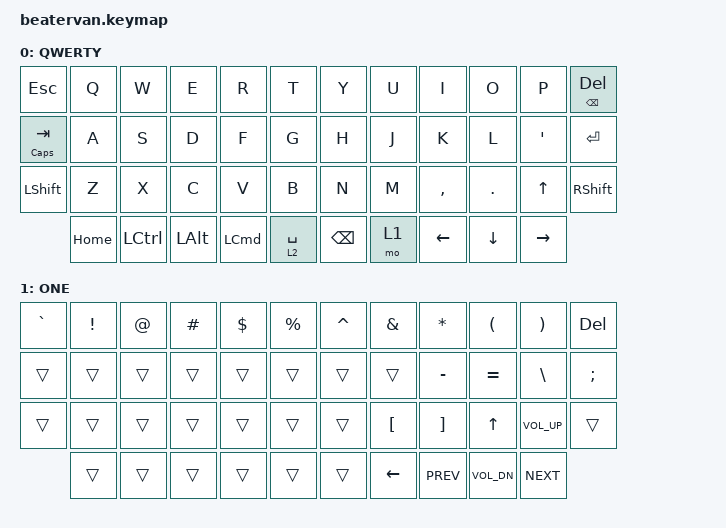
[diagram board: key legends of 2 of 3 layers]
/*
 * Copyright (c) 2020 The ZMK Contributors
 *
 * SPDX-License-Identifier: MIT
 */

#include <behaviors.dtsi>
#include <dt-bindings/zmk/keys.h>
#include <dt-bindings/zmk/bt.h>

#define QWERTY 0
#define ONE 1
#define TWO 2

/ {
	behaviors {
		ht: hold_tap {
			compatible = "zmk,behavior-hold-tap";
			label = "Hold Tap";
			#binding-cells = <2>;
			tapping-term-ms = <200>;
			flavor = "tap-preferred";
			bindings = <&kp>, <&kp>;
		};
	};

	keymap {
		compatible = "zmk,keymap";

		default_layer {
			label = "QWERTY";
			bindings = <
&kp ESC      &kp Q    &kp W    &kp E       &kp R &kp T &kp Y &kp U    &kp I     &kp O    &kp P    &ht BSPC DEL
&ht CAPS TAB   &kp A    &kp S    &kp D       &kp F &kp G &kp H &kp J    &kp K     &kp L    &kp APOS &kp RET
&kp LSHFT         &kp Z    &kp X    &kp C       &kp V &kp B &kp N &kp M    &kp COMMA &kp DOT  &kp UP   &kp RSHFT
&kp HOME     &kp LCTRL &kp LALT &kp LCMD         &lt 2 SPACE   &kp BSPC &mo 1     &kp LEFT &kp DOWN &kp RIGHT
			>;
		};

		first_layer {
			label = "ONE";
			bindings = <
&kp GRAVE &kp EXCL &kp AT &kp HASH &kp DOLLAR &kp PERCENT &kp CARET &kp AMPS &kp STAR &kp LPAR &kp RPAR &kp DEL
&trans     &trans &trans &trans &trans &trans &trans &trans &kp MINUS &kp EQUAL &kp BSLH  &kp SEMI
&trans    &trans  &trans &trans &trans &trans &trans   &kp LBKT   &kp RBKT    &kp UP    &kp C_VOL_UP   &trans
&trans    &trans   &trans    &trans                        &trans   &trans    &kp LEFT  &kp C_PREV    &kp C_VOL_DN &kp C_NEXT
			>;
		};

		second_layer {
			label = "TWO";
			bindings = <
&trans &kp N7 &kp N8 &kp N9 &bt BT_CLR &bt BT_PRV &bt BT_NXT &trans &trans  &trans  &trans  &trans
&trans &kp N4 &kp N5 &kp N6 &trans     &trans     &trans     &trans &trans  &trans  &trans  &trans
&trans &kp N1 &kp N2 &kp N3 &kp N0     &trans     &trans     &trans &trans  &trans  &trans  &trans
&trans    &trans     &trans     &trans        &trans &trans &trans                  &trans  &trans
			>;
		};

	};
};
